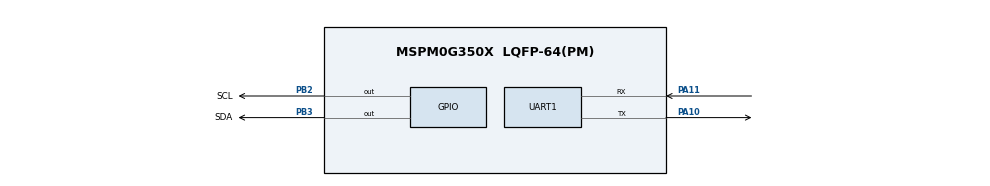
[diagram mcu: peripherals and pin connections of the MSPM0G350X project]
/**
 * @cliArgs --device "MSPM0G350X" --part "Default" --package "LQFP-64(PM)" --product "mspm0_sdk@2.10.00.04"
 * @versions {"tool":"1.26.2+4477"}
 */
const GPIO   = scripting.addModule("/ti/driverlib/GPIO", {}, false);
const GPIO1  = GPIO.addInstance();
const UART   = scripting.addModule("/ti/driverlib/UART", {}, false);
const UART1  = UART.addInstance();
const SYSCTL = scripting.addModule("/ti/driverlib/SYSCTL");

GPIO1.$name                          = "I2C";
GPIO1.associatedPins.create(2);
GPIO1.associatedPins[0].$name        = "SCL";
GPIO1.associatedPins[0].initialValue = "SET";
GPIO1.associatedPins[0].pin.$assign  = "PB2";
GPIO1.associatedPins[1].$name        = "SDA";
GPIO1.associatedPins[1].initialValue = "SET";
GPIO1.associatedPins[1].pin.$assign  = "PB3";

UART1.$name                    = "UART_0";
UART1.profile                  = "CONFIG_PROFILE_1";
UART1.peripheral.$assign       = "UART0";
UART1.targetBaudRate           = 9600;
UART1.enableFIFO               = false;
UART1.peripheral.rxPin.$assign = "PA11";
UART1.peripheral.txPin.$assign = "PA10";
const Board = scripting.addModule("/ti/driverlib/Board", {}, false);

SYSCTL.forceDefaultClkConfig = true;
Board.peripheral.$suggestSolution          = "DEBUGSS";
Board.peripheral.swclkPin.$suggestSolution = "PA20";
Board.peripheral.swdioPin.$suggestSolution = "PA19";
SYSCTL.peripheral.$suggestSolution         = "SYSCTL";
